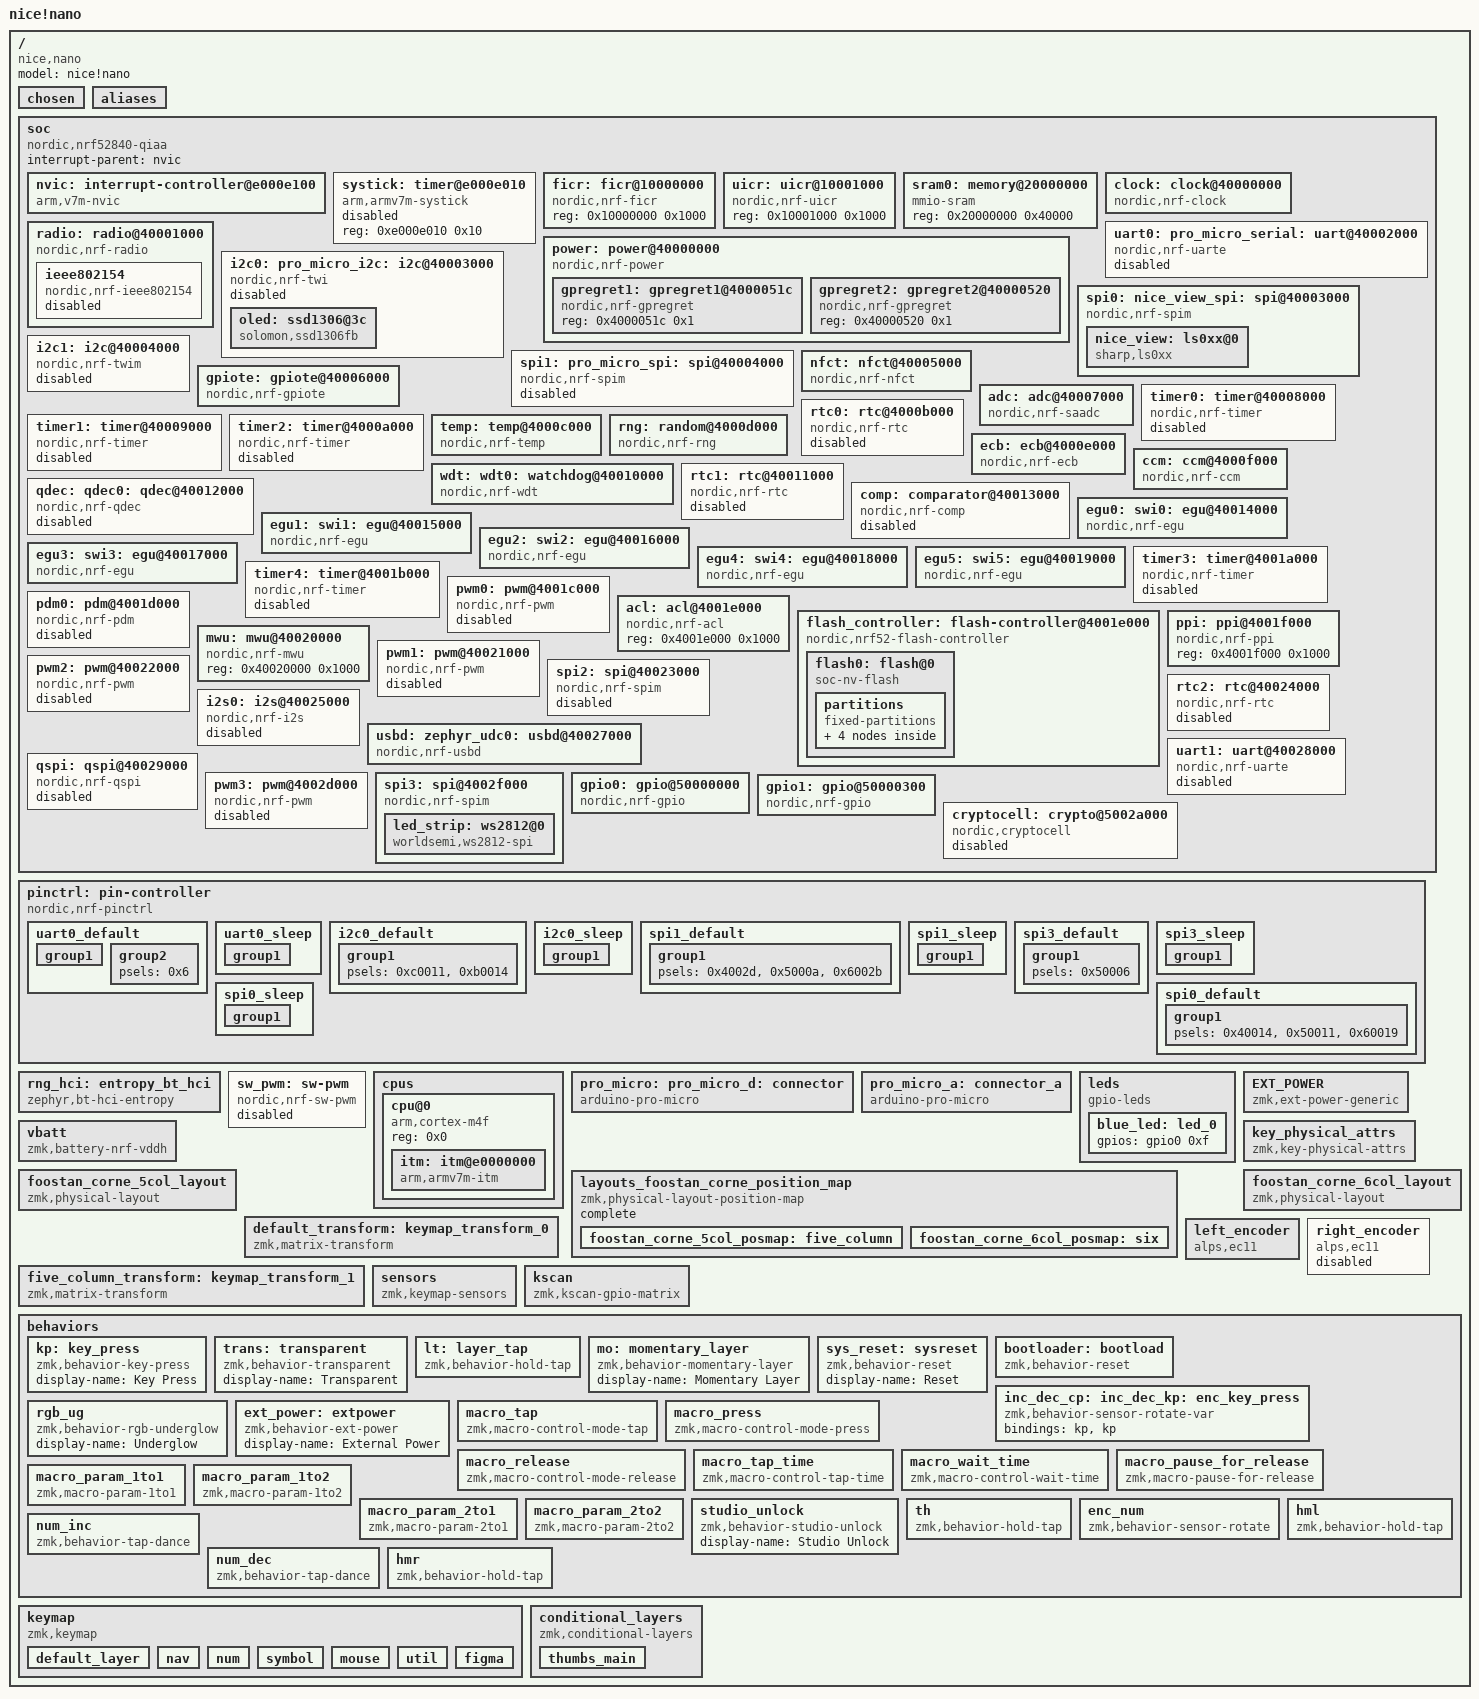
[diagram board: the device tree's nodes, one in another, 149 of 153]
/dts-v1/;

/ {
	#address-cells = < 0x1 >;
	#size-cells = < 0x1 >;
	model = "nice!nano";
	compatible = "nice,nano";
	chosen {
		zephyr,entropy = &rng;
		zephyr,flash-controller = &flash_controller;
		zephyr,code-partition = &code_partition;
		zephyr,sram = &sram0;
		zephyr,flash = &flash0;
		zmk,battery = &vbatt;
		zephyr,display = &nice_view;
		zmk,physical-layout = &foostan_corne_6col_layout;
		zmk,kscan = &kscan;
		zmk,underglow = &led_strip;
	};
	aliases {
	};
	soc {
		#address-cells = < 0x1 >;
		#size-cells = < 0x1 >;
		compatible = "nordic,nrf52840-qiaa", "nordic,nrf52840", "nordic,nrf52", "simple-bus";
		interrupt-parent = < &nvic >;
		ranges;
		nvic: interrupt-controller@e000e100 {
			#address-cells = < 0x1 >;
			compatible = "arm,v7m-nvic";
			reg = < 0xe000e100 0xc00 >;
			interrupt-controller;
			#interrupt-cells = < 0x2 >;
			arm,num-irq-priority-bits = < 0x3 >;
			phandle = < 0x1 >;
		};
		systick: timer@e000e010 {
			compatible = "arm,armv7m-systick";
			reg = < 0xe000e010 0x10 >;
			status = "disabled";
		};
		ficr: ficr@10000000 {
			compatible = "nordic,nrf-ficr";
			reg = < 0x10000000 0x1000 >;
			status = "okay";
		};
		uicr: uicr@10001000 {
			compatible = "nordic,nrf-uicr";
			reg = < 0x10001000 0x1000 >;
			status = "okay";
		};
		sram0: memory@20000000 {
			compatible = "mmio-sram";
			reg = < 0x20000000 0x40000 >;
		};
		clock: clock@40000000 {
			compatible = "nordic,nrf-clock";
			reg = < 0x40000000 0x1000 >;
			interrupts = < 0x0 0x1 >;
			status = "okay";
		};
		power: power@40000000 {
			compatible = "nordic,nrf-power";
			reg = < 0x40000000 0x1000 >;
			interrupts = < 0x0 0x1 >;
			status = "okay";
			#address-cells = < 0x1 >;
			#size-cells = < 0x1 >;
			gpregret1: gpregret1@4000051c {
				#address-cells = < 0x1 >;
				#size-cells = < 0x1 >;
				compatible = "nordic,nrf-gpregret";
				reg = < 0x4000051c 0x1 >;
				status = "okay";
			};
			gpregret2: gpregret2@40000520 {
				#address-cells = < 0x1 >;
				#size-cells = < 0x1 >;
				compatible = "nordic,nrf-gpregret";
				reg = < 0x40000520 0x1 >;
				status = "okay";
			};
		};
		radio: radio@40001000 {
			compatible = "nordic,nrf-radio";
			reg = < 0x40001000 0x1000 >;
			interrupts = < 0x1 0x1 >;
			status = "okay";
			ieee802154-supported;
			ble-2mbps-supported;
			ble-coded-phy-supported;
			tx-high-power-supported;
			ieee802154: ieee802154 {
				compatible = "nordic,nrf-ieee802154";
				status = "disabled";
			};
		};
		uart0: pro_micro_serial: uart@40002000 {
			compatible = "nordic,nrf-uarte";
			reg = < 0x40002000 0x1000 >;
			interrupts = < 0x2 0x1 >;
			status = "disabled";
			current-speed = < 0x1c200 >;
			pinctrl-0 = < &uart0_default >;
			pinctrl-1 = < &uart0_sleep >;
			pinctrl-names = "default", "sleep";
		};
		i2c0: pro_micro_i2c: i2c@40003000 {
			compatible = "nordic,nrf-twi";
			#address-cells = < 0x1 >;
			#size-cells = < 0x0 >;
			reg = < 0x40003000 0x1000 >;
			clock-frequency = < 0x186a0 >;
			interrupts = < 0x3 0x1 >;
			easydma-maxcnt-bits = < 0x10 >;
			status = "disabled";
			pinctrl-0 = < &i2c0_default >;
			pinctrl-1 = < &i2c0_sleep >;
			pinctrl-names = "default", "sleep";
			oled: ssd1306@3c {
				compatible = "solomon,ssd1306fb";
				reg = < 0x3c >;
				width = < 0x80 >;
				height = < 0x20 >;
				segment-offset = < 0x0 >;
				page-offset = < 0x0 >;
				display-offset = < 0x0 >;
				multiplex-ratio = < 0x1f >;
				segment-remap;
				com-invdir;
				com-sequential;
				inversion-on;
				prechargep = < 0x22 >;
			};
		};
		spi0: nice_view_spi: spi@40003000 {
			compatible = "nordic,nrf-spim";
			#address-cells = < 0x1 >;
			#size-cells = < 0x0 >;
			reg = < 0x40003000 0x1000 >;
			interrupts = < 0x3 0x1 >;
			max-frequency = < 0x7a1200 >;
			easydma-maxcnt-bits = < 0x10 >;
			status = "okay";
			pinctrl-0 = < &spi0_default >;
			pinctrl-1 = < &spi0_sleep >;
			pinctrl-names = "default", "sleep";
			cs-gpios = < &pro_micro 0x1 0x0 >;
			nice_view: ls0xx@0 {
				compatible = "sharp,ls0xx";
				spi-max-frequency = < 0xf4240 >;
				reg = < 0x0 >;
				width = < 0xa0 >;
				height = < 0x44 >;
			};
		};
		i2c1: i2c@40004000 {
			compatible = "nordic,nrf-twim";
			#address-cells = < 0x1 >;
			#size-cells = < 0x0 >;
			reg = < 0x40004000 0x1000 >;
			clock-frequency = < 0x186a0 >;
			interrupts = < 0x4 0x1 >;
			easydma-maxcnt-bits = < 0x10 >;
			status = "disabled";
		};
		spi1: pro_micro_spi: spi@40004000 {
			compatible = "nordic,nrf-spim";
			#address-cells = < 0x1 >;
			#size-cells = < 0x0 >;
			reg = < 0x40004000 0x1000 >;
			interrupts = < 0x4 0x1 >;
			max-frequency = < 0x7a1200 >;
			easydma-maxcnt-bits = < 0x10 >;
			status = "disabled";
			pinctrl-0 = < &spi1_default >;
			pinctrl-1 = < &spi1_sleep >;
			pinctrl-names = "default", "sleep";
		};
		nfct: nfct@40005000 {
			compatible = "nordic,nrf-nfct";
			reg = < 0x40005000 0x1000 >;
			interrupts = < 0x5 0x1 >;
			status = "okay";
		};
		gpiote: gpiote@40006000 {
			compatible = "nordic,nrf-gpiote";
			reg = < 0x40006000 0x1000 >;
			interrupts = < 0x6 0x5 >;
			status = "okay";
		};
		adc: adc@40007000 {
			compatible = "nordic,nrf-saadc";
			reg = < 0x40007000 0x1000 >;
			interrupts = < 0x7 0x1 >;
			status = "okay";
			#io-channel-cells = < 0x1 >;
		};
		timer0: timer@40008000 {
			compatible = "nordic,nrf-timer";
			status = "disabled";
			reg = < 0x40008000 0x1000 >;
			cc-num = < 0x4 >;
			max-bit-width = < 0x20 >;
			interrupts = < 0x8 0x1 >;
			prescaler = < 0x0 >;
		};
		timer1: timer@40009000 {
			compatible = "nordic,nrf-timer";
			status = "disabled";
			reg = < 0x40009000 0x1000 >;
			cc-num = < 0x4 >;
			max-bit-width = < 0x20 >;
			interrupts = < 0x9 0x1 >;
			prescaler = < 0x0 >;
			phandle = < 0xd >;
		};
		timer2: timer@4000a000 {
			compatible = "nordic,nrf-timer";
			status = "disabled";
			reg = < 0x4000a000 0x1000 >;
			cc-num = < 0x4 >;
			max-bit-width = < 0x20 >;
			interrupts = < 0xa 0x1 >;
			prescaler = < 0x0 >;
		};
		rtc0: rtc@4000b000 {
			compatible = "nordic,nrf-rtc";
			reg = < 0x4000b000 0x1000 >;
			cc-num = < 0x3 >;
			interrupts = < 0xb 0x1 >;
			status = "disabled";
			clock-frequency = < 0x8000 >;
			prescaler = < 0x1 >;
		};
		temp: temp@4000c000 {
			compatible = "nordic,nrf-temp";
			reg = < 0x4000c000 0x1000 >;
			interrupts = < 0xc 0x1 >;
			status = "okay";
		};
		rng: random@4000d000 {
			compatible = "nordic,nrf-rng";
			reg = < 0x4000d000 0x1000 >;
			interrupts = < 0xd 0x1 >;
			status = "okay";
		};
		ecb: ecb@4000e000 {
			compatible = "nordic,nrf-ecb";
			reg = < 0x4000e000 0x1000 >;
			interrupts = < 0xe 0x1 >;
			status = "okay";
		};
		ccm: ccm@4000f000 {
			compatible = "nordic,nrf-ccm";
			reg = < 0x4000f000 0x1000 >;
			interrupts = < 0xf 0x1 >;
			length-field-length-8-bits;
			status = "okay";
		};
		wdt: wdt0: watchdog@40010000 {
			compatible = "nordic,nrf-wdt";
			reg = < 0x40010000 0x1000 >;
			interrupts = < 0x10 0x1 >;
			status = "okay";
		};
		rtc1: rtc@40011000 {
			compatible = "nordic,nrf-rtc";
			reg = < 0x40011000 0x1000 >;
			cc-num = < 0x4 >;
			interrupts = < 0x11 0x1 >;
			status = "disabled";
			clock-frequency = < 0x8000 >;
			prescaler = < 0x1 >;
		};
		qdec: qdec0: qdec@40012000 {
			compatible = "nordic,nrf-qdec";
			reg = < 0x40012000 0x1000 >;
			interrupts = < 0x12 0x1 >;
			status = "disabled";
		};
		comp: comparator@40013000 {
			compatible = "nordic,nrf-comp";
			reg = < 0x40013000 0x1000 >;
			interrupts = < 0x13 0x1 >;
			status = "disabled";
			#io-channel-cells = < 0x1 >;
		};
		egu0: swi0: egu@40014000 {
			compatible = "nordic,nrf-egu", "nordic,nrf-swi";
			reg = < 0x40014000 0x1000 >;
			interrupts = < 0x14 0x1 >;
			status = "okay";
		};
		egu1: swi1: egu@40015000 {
			compatible = "nordic,nrf-egu", "nordic,nrf-swi";
			reg = < 0x40015000 0x1000 >;
			interrupts = < 0x15 0x1 >;
			status = "okay";
		};
		egu2: swi2: egu@40016000 {
			compatible = "nordic,nrf-egu", "nordic,nrf-swi";
			reg = < 0x40016000 0x1000 >;
			interrupts = < 0x16 0x1 >;
			status = "okay";
		};
		egu3: swi3: egu@40017000 {
			compatible = "nordic,nrf-egu", "nordic,nrf-swi";
			reg = < 0x40017000 0x1000 >;
			interrupts = < 0x17 0x1 >;
			status = "okay";
		};
		egu4: swi4: egu@40018000 {
			compatible = "nordic,nrf-egu", "nordic,nrf-swi";
			reg = < 0x40018000 0x1000 >;
			interrupts = < 0x18 0x1 >;
			status = "okay";
		};
		egu5: swi5: egu@40019000 {
			compatible = "nordic,nrf-egu", "nordic,nrf-swi";
			reg = < 0x40019000 0x1000 >;
			interrupts = < 0x19 0x1 >;
			status = "okay";
		};
		timer3: timer@4001a000 {
			compatible = "nordic,nrf-timer";
			status = "disabled";
			reg = < 0x4001a000 0x1000 >;
			cc-num = < 0x6 >;
			max-bit-width = < 0x20 >;
			interrupts = < 0x1a 0x1 >;
			prescaler = < 0x0 >;
		};
		timer4: timer@4001b000 {
			compatible = "nordic,nrf-timer";
			status = "disabled";
			reg = < 0x4001b000 0x1000 >;
			cc-num = < 0x6 >;
			max-bit-width = < 0x20 >;
			interrupts = < 0x1b 0x1 >;
			prescaler = < 0x0 >;
		};
		pwm0: pwm@4001c000 {
			compatible = "nordic,nrf-pwm";
			reg = < 0x4001c000 0x1000 >;
			interrupts = < 0x1c 0x1 >;
			status = "disabled";
			#pwm-cells = < 0x3 >;
		};
		pdm0: pdm@4001d000 {
			compatible = "nordic,nrf-pdm";
			reg = < 0x4001d000 0x1000 >;
			interrupts = < 0x1d 0x1 >;
			status = "disabled";
		};
		acl: acl@4001e000 {
			compatible = "nordic,nrf-acl";
			reg = < 0x4001e000 0x1000 >;
			status = "okay";
		};
		flash_controller: flash-controller@4001e000 {
			compatible = "nordic,nrf52-flash-controller";
			reg = < 0x4001e000 0x1000 >;
			partial-erase;
			#address-cells = < 0x1 >;
			#size-cells = < 0x1 >;
			flash0: flash@0 {
				compatible = "soc-nv-flash";
				erase-block-size = < 0x1000 >;
				write-block-size = < 0x4 >;
				reg = < 0x0 0x100000 >;
				partitions {
					compatible = "fixed-partitions";
					#address-cells = < 0x1 >;
					#size-cells = < 0x1 >;
					sd_partition: partition@0 {
						reg = < 0x0 0x26000 >;
					};
					code_partition: partition@26000 {
						reg = < 0x26000 0xc6000 >;
					};
					storage_partition: partition@ec000 {
						reg = < 0xec000 0x8000 >;
					};
					boot_partition: partition@f4000 {
						reg = < 0xf4000 0xc000 >;
					};
				};
			};
		};
		ppi: ppi@4001f000 {
			compatible = "nordic,nrf-ppi";
			reg = < 0x4001f000 0x1000 >;
			status = "okay";
		};
		mwu: mwu@40020000 {
			compatible = "nordic,nrf-mwu";
			reg = < 0x40020000 0x1000 >;
			status = "okay";
		};
		pwm1: pwm@40021000 {
			compatible = "nordic,nrf-pwm";
			reg = < 0x40021000 0x1000 >;
			interrupts = < 0x21 0x1 >;
			status = "disabled";
			#pwm-cells = < 0x3 >;
		};
		pwm2: pwm@40022000 {
			compatible = "nordic,nrf-pwm";
			reg = < 0x40022000 0x1000 >;
			interrupts = < 0x22 0x1 >;
			status = "disabled";
			#pwm-cells = < 0x3 >;
		};
		spi2: spi@40023000 {
			compatible = "nordic,nrf-spim";
			#address-cells = < 0x1 >;
			#size-cells = < 0x0 >;
			reg = < 0x40023000 0x1000 >;
			interrupts = < 0x23 0x1 >;
			max-frequency = < 0x7a1200 >;
			easydma-maxcnt-bits = < 0x10 >;
			status = "disabled";
		};
		rtc2: rtc@40024000 {
			compatible = "nordic,nrf-rtc";
			reg = < 0x40024000 0x1000 >;
			cc-num = < 0x4 >;
			interrupts = < 0x24 0x1 >;
			status = "disabled";
			clock-frequency = < 0x8000 >;
			prescaler = < 0x1 >;
		};
		i2s0: i2s@40025000 {
			compatible = "nordic,nrf-i2s";
			#address-cells = < 0x1 >;
			#size-cells = < 0x0 >;
			reg = < 0x40025000 0x1000 >;
			interrupts = < 0x25 0x1 >;
			status = "disabled";
		};
		usbd: zephyr_udc0: usbd@40027000 {
			compatible = "nordic,nrf-usbd";
			reg = < 0x40027000 0x1000 >;
			interrupts = < 0x27 0x1 >;
			num-bidir-endpoints = < 0x1 >;
			num-in-endpoints = < 0x7 >;
			num-out-endpoints = < 0x7 >;
			num-isoin-endpoints = < 0x1 >;
			num-isoout-endpoints = < 0x1 >;
			status = "okay";
		};
		uart1: uart@40028000 {
			compatible = "nordic,nrf-uarte";
			reg = < 0x40028000 0x1000 >;
			interrupts = < 0x28 0x1 >;
			status = "disabled";
		};
		qspi: qspi@40029000 {
			compatible = "nordic,nrf-qspi";
			#address-cells = < 0x1 >;
			#size-cells = < 0x0 >;
			reg = < 0x40029000 0x1000 >, < 0x12000000 0x8000000 >;
			reg-names = "qspi", "qspi_mm";
			interrupts = < 0x29 0x1 >;
			status = "disabled";
		};
		pwm3: pwm@4002d000 {
			compatible = "nordic,nrf-pwm";
			reg = < 0x4002d000 0x1000 >;
			interrupts = < 0x2d 0x1 >;
			status = "disabled";
			#pwm-cells = < 0x3 >;
		};
		spi3: spi@4002f000 {
			compatible = "nordic,nrf-spim";
			#address-cells = < 0x1 >;
			#size-cells = < 0x0 >;
			reg = < 0x4002f000 0x1000 >;
			interrupts = < 0x2f 0x1 >;
			max-frequency = < 0x1e84800 >;
			easydma-maxcnt-bits = < 0x10 >;
			rx-delay-supported;
			rx-delay = < 0x2 >;
			status = "okay";
			pinctrl-0 = < &spi3_default >;
			pinctrl-1 = < &spi3_sleep >;
			pinctrl-names = "default", "sleep";
			led_strip: ws2812@0 {
				compatible = "worldsemi,ws2812-spi";
				reg = < 0x0 >;
				spi-max-frequency = < 0x3d0900 >;
				chain-length = < 0xa >;
				spi-one-frame = < 0x70 >;
				spi-zero-frame = < 0x40 >;
				color-mapping = < 0x2 0x1 0x3 >;
			};
		};
		gpio0: gpio@50000000 {
			compatible = "nordic,nrf-gpio";
			gpio-controller;
			reg = < 0x50000000 0x200 0x50000500 0x300 >;
			#gpio-cells = < 0x2 >;
			status = "okay";
			port = < 0x0 >;
			phandle = < 0xe >;
		};
		gpio1: gpio@50000300 {
			compatible = "nordic,nrf-gpio";
			gpio-controller;
			reg = < 0x50000300 0x200 0x50000800 0x300 >;
			#gpio-cells = < 0x2 >;
			ngpios = < 0x10 >;
			status = "okay";
			port = < 0x1 >;
			phandle = < 0xf >;
		};
		cryptocell: crypto@5002a000 {
			compatible = "nordic,cryptocell", "arm,cryptocell-310";
			reg = < 0x5002a000 0x1000 >, < 0x5002b000 0x1000 >;
			reg-names = "wrapper", "core";
			interrupts = < 0x2a 0x1 >;
			status = "disabled";
		};
	};
	pinctrl: pin-controller {
		compatible = "nordic,nrf-pinctrl";
		uart0_default: uart0_default {
			phandle = < 0x2 >;
			group1 {
				psels = < 0x10008 >;
				bias-pull-up;
			};
			group2 {
				psels = < 0x6 >;
			};
		};
		uart0_sleep: uart0_sleep {
			phandle = < 0x3 >;
			group1 {
				psels = < 0x10008 >, < 0x6 >;
				low-power-enable;
			};
		};
		i2c0_default: i2c0_default {
			phandle = < 0x4 >;
			group1 {
				psels = < 0xc0011 >, < 0xb0014 >;
			};
		};
		i2c0_sleep: i2c0_sleep {
			phandle = < 0x5 >;
			group1 {
				psels = < 0xc0011 >, < 0xb0014 >;
				low-power-enable;
			};
		};
		spi1_default: spi1_default {
			phandle = < 0x9 >;
			group1 {
				psels = < 0x4002d >, < 0x5000a >, < 0x6002b >;
			};
		};
		spi1_sleep: spi1_sleep {
			phandle = < 0xa >;
			group1 {
				psels = < 0x4002d >, < 0x5000a >, < 0x6002b >;
				low-power-enable;
			};
		};
		spi3_default: spi3_default {
			phandle = < 0xb >;
			group1 {
				psels = < 0x50006 >;
			};
		};
		spi3_sleep: spi3_sleep {
			phandle = < 0xc >;
			group1 {
				psels = < 0x50006 >;
				low-power-enable;
			};
		};
		spi0_default: spi0_default {
			phandle = < 0x6 >;
			group1 {
				psels = < 0x40014 >, < 0x50011 >, < 0x60019 >;
			};
		};
		spi0_sleep: spi0_sleep {
			phandle = < 0x7 >;
			group1 {
				psels = < 0x40014 >, < 0x50011 >, < 0x60019 >;
				low-power-enable;
			};
		};
	};
	rng_hci: entropy_bt_hci {
		compatible = "zephyr,bt-hci-entropy";
		status = "okay";
	};
	sw_pwm: sw-pwm {
		compatible = "nordic,nrf-sw-pwm";
		status = "disabled";
		generator = < &timer1 >;
		clock-prescaler = < 0x0 >;
		#pwm-cells = < 0x3 >;
	};
	cpus {
		#address-cells = < 0x1 >;
		#size-cells = < 0x0 >;
		cpu@0 {
			device_type = "cpu";
			compatible = "arm,cortex-m4f";
			reg = < 0x0 >;
			#address-cells = < 0x1 >;
			#size-cells = < 0x1 >;
			itm: itm@e0000000 {
				compatible = "arm,armv7m-itm";
				reg = < 0xe0000000 0x1000 >;
				swo-ref-frequency = < 0x1e84800 >;
			};
		};
	};
	pro_micro: pro_micro_d: connector {
		compatible = "arduino-pro-micro";
		#gpio-cells = < 0x2 >;
		gpio-map-mask = < 0xffffffff 0xffffffc0 >;
		gpio-map-pass-thru = < 0x0 0x3f >;
		gpio-map = < 0x0 0x0 &gpio0 0x8 0x0 >, < 0x1 0x0 &gpio0 0x6 0x0 >, < 0x2 0x0 &gpio0 0x11 0x0 >, < 0x3 0x0 &gpio0 0x14 0x0 >, < 0x4 0x0 &gpio0 0x16 0x0 >, < 0x5 0x0 &gpio0 0x18 0x0 >, < 0x6 0x0 &gpio1 0x0 0x0 >, < 0x7 0x0 &gpio0 0xb 0x0 >, < 0x8 0x0 &gpio1 0x4 0x0 >, < 0x9 0x0 &gpio1 0x6 0x0 >, < 0xa 0x0 &gpio0 0x9 0x0 >, < 0x10 0x0 &gpio0 0xa 0x0 >, < 0xe 0x0 &gpio1 0xb 0x0 >, < 0xf 0x0 &gpio1 0xd 0x0 >, < 0x12 0x0 &gpio1 0xf 0x0 >, < 0x13 0x0 &gpio0 0x2 0x0 >, < 0x14 0x0 &gpio0 0x1d 0x0 >, < 0x15 0x0 &gpio0 0x1f 0x0 >;
		phandle = < 0x8 >;
	};
	pro_micro_a: connector_a {
		compatible = "arduino-pro-micro";
		#gpio-cells = < 0x2 >;
		gpio-map-mask = < 0xffffffff 0xffffffc0 >;
		gpio-map-pass-thru = < 0x0 0x3f >;
		gpio-map = < 0x0 0x0 &gpio1 0xf 0x0 >, < 0x1 0x0 &gpio0 0x2 0x0 >, < 0x2 0x0 &gpio0 0x1d 0x0 >, < 0x3 0x0 &gpio0 0x1f 0x0 >, < 0x6 0x0 &gpio0 0x16 0x0 >, < 0x7 0x0 &gpio1 0x0 0x0 >, < 0x8 0x0 &gpio1 0x4 0x0 >, < 0x9 0x0 &gpio1 0x6 0x0 >, < 0xa 0x0 &gpio0 0x9 0x0 >;
	};
	leds {
		compatible = "gpio-leds";
		blue_led: led_0 {
			gpios = < &gpio0 0xf 0x0 >;
		};
	};
	EXT_POWER {
		compatible = "zmk,ext-power-generic";
		control-gpios = < &gpio0 0xd 0x0 >;
		init-delay-ms = < 0x32 >;
	};
	vbatt: vbatt {
		compatible = "zmk,battery-nrf-vddh";
	};
	layouts_foostan_corne_position_map: layouts_foostan_corne_position_map {
		compatible = "zmk,physical-layout-position-map";
		complete;
		foostan_corne_5col_posmap: five_column {
			physical-layout = < &foostan_corne_5col_layout >;
			positions = < 0x24 0x0 0x1 0x2 0x3 0x4 0x5 0x6 0x7 0x8 0x9 0x25 >, < 0x26 0xa 0xb 0xc 0xd 0xe 0xf 0x10 0x11 0x12 0x13 0x27 >, < 0x28 0x14 0x15 0x16 0x17 0x18 0x19 0x1a 0x1b 0x1c 0x1d 0x29 >, < 0x1e 0x1f 0x20 0x21 0x22 0x23 >;
		};
		foostan_corne_6col_posmap: six {
			physical-layout = < &foostan_corne_6col_layout >;
			positions = < 0x0 0x1 0x2 0x3 0x4 0x5 0x6 0x7 0x8 0x9 0xa 0xb >, < 0xc 0xd 0xe 0xf 0x10 0x11 0x12 0x13 0x14 0x15 0x16 0x17 >, < 0x18 0x19 0x1a 0x1b 0x1c 0x1d 0x1e 0x1f 0x20 0x21 0x22 0x23 >, < 0x24 0x25 0x26 0x27 0x28 0x29 >;
		};
	};
	key_physical_attrs: key_physical_attrs {
		compatible = "zmk,key-physical-attrs";
		#key-cells = < 0x7 >;
		phandle = < 0x12 >;
	};
	foostan_corne_5col_layout: foostan_corne_5col_layout {
		compatible = "zmk,physical-layout";
		display-name = "5 Column";
		keys = < &key_physical_attrs 0x64 0x64 0x0 0x25 0x0 0x0 0x0 >, < &key_physical_attrs 0x64 0x64 0x64 0xc 0x0 0x0 0x0 >, < &key_physical_attrs 0x64 0x64 0xc8 0x0 0x0 0x0 0x0 >, < &key_physical_attrs 0x64 0x64 0x12c 0xc 0x0 0x0 0x0 >, < &key_physical_attrs 0x64 0x64 0x190 0x18 0x0 0x0 0x0 >, < &key_physical_attrs 0x64 0x64 0x2bc 0x18 0x0 0x0 0x0 >, < &key_physical_attrs 0x64 0x64 0x320 0xc 0x0 0x0 0x0 >, < &key_physical_attrs 0x64 0x64 0x384 0x0 0x0 0x0 0x0 >, < &key_physical_attrs 0x64 0x64 0x3e8 0xc 0x0 0x0 0x0 >, < &key_physical_attrs 0x64 0x64 0x44c 0x25 0x0 0x0 0x0 >, < &key_physical_attrs 0x64 0x64 0x0 0x89 0x0 0x0 0x0 >, < &key_physical_attrs 0x64 0x64 0x64 0x70 0x0 0x0 0x0 >, < &key_physical_attrs 0x64 0x64 0xc8 0x64 0x0 0x0 0x0 >, < &key_physical_attrs 0x64 0x64 0x12c 0x70 0x0 0x0 0x0 >, < &key_physical_attrs 0x64 0x64 0x190 0x7c 0x0 0x0 0x0 >, < &key_physical_attrs 0x64 0x64 0x2bc 0x7c 0x0 0x0 0x0 >, < &key_physical_attrs 0x64 0x64 0x320 0x70 0x0 0x0 0x0 >, < &key_physical_attrs 0x64 0x64 0x384 0x64 0x0 0x0 0x0 >, < &key_physical_attrs 0x64 0x64 0x3e8 0x70 0x0 0x0 0x0 >, < &key_physical_attrs 0x64 0x64 0x44c 0x89 0x0 0x0 0x0 >, < &key_physical_attrs 0x64 0x64 0x0 0xed 0x0 0x0 0x0 >, < &key_physical_attrs 0x64 0x64 0x64 0xd4 0x0 0x0 0x0 >, < &key_physical_attrs 0x64 0x64 0xc8 0xc8 0x0 0x0 0x0 >, < &key_physical_attrs 0x64 0x64 0x12c 0xd4 0x0 0x0 0x0 >, < &key_physical_attrs 0x64 0x64 0x190 0xe0 0x0 0x0 0x0 >, < &key_physical_attrs 0x64 0x64 0x2bc 0xe0 0x0 0x0 0x0 >, < &key_physical_attrs 0x64 0x64 0x320 0xd4 0x0 0x0 0x0 >, < &key_physical_attrs 0x64 0x64 0x384 0xc8 0x0 0x0 0x0 >, < &key_physical_attrs 0x64 0x64 0x3e8 0xd4 0x0 0x0 0x0 >, < &key_physical_attrs 0x64 0x64 0x44c 0xed 0x0 0x0 0x0 >, < &key_physical_attrs 0x64 0x64 0xfa 0x138 0x0 0x0 0x0 >, < &key_physical_attrs 0x64 0x64 0x15e 0x138 0x4b0 0x15e 0x19c >, < &key_physical_attrs 0x64 0x96 0x1c0 0x11b 0x960 0x1c0 0x1b1 >, < &key_physical_attrs 0x64 0x96 0x28c 0x11b 0xfffff6a0 0x2f0 0x1b1 >, < &key_physical_attrs 0x64 0x64 0x2ee 0x138 0xfffffb50 0x352 0x19c >, < &key_physical_attrs 0x64 0x64 0x352 0x138 0x0 0x0 0x0 >;
		transform = < &five_column_transform >;
		phandle = < 0x10 >;
	};
	foostan_corne_6col_layout: foostan_corne_6col_layout {
		compatible = "zmk,physical-layout";
		display-name = "6 Column";
		keys = < &key_physical_attrs 0x64 0x64 0x0 0x25 0x0 0x0 0x0 >, < &key_physical_attrs 0x64 0x64 0x64 0x25 0x0 0x0 0x0 >, < &key_physical_attrs 0x64 0x64 0xc8 0xc 0x0 0x0 0x0 >, < &key_physical_attrs 0x64 0x64 0x12c 0x0 0x0 0x0 0x0 >, < &key_physical_attrs 0x64 0x64 0x190 0xc 0x0 0x0 0x0 >, < &key_physical_attrs 0x64 0x64 0x1f4 0x18 0x0 0x0 0x0 >, < &key_physical_attrs 0x64 0x64 0x320 0x18 0x0 0x0 0x0 >, < &key_physical_attrs 0x64 0x64 0x384 0xc 0x0 0x0 0x0 >, < &key_physical_attrs 0x64 0x64 0x3e8 0x0 0x0 0x0 0x0 >, < &key_physical_attrs 0x64 0x64 0x44c 0xc 0x0 0x0 0x0 >, < &key_physical_attrs 0x64 0x64 0x4b0 0x25 0x0 0x0 0x0 >, < &key_physical_attrs 0x64 0x64 0x514 0x25 0x0 0x0 0x0 >, < &key_physical_attrs 0x64 0x64 0x0 0x89 0x0 0x0 0x0 >, < &key_physical_attrs 0x64 0x64 0x64 0x89 0x0 0x0 0x0 >, < &key_physical_attrs 0x64 0x64 0xc8 0x70 0x0 0x0 0x0 >, < &key_physical_attrs 0x64 0x64 0x12c 0x64 0x0 0x0 0x0 >, < &key_physical_attrs 0x64 0x64 0x190 0x70 0x0 0x0 0x0 >, < &key_physical_attrs 0x64 0x64 0x1f4 0x7c 0x0 0x0 0x0 >, < &key_physical_attrs 0x64 0x64 0x320 0x7c 0x0 0x0 0x0 >, < &key_physical_attrs 0x64 0x64 0x384 0x70 0x0 0x0 0x0 >, < &key_physical_attrs 0x64 0x64 0x3e8 0x64 0x0 0x0 0x0 >, < &key_physical_attrs 0x64 0x64 0x44c 0x70 0x0 0x0 0x0 >, < &key_physical_attrs 0x64 0x64 0x4b0 0x89 0x0 0x0 0x0 >, < &key_physical_attrs 0x64 0x64 0x514 0x89 0x0 0x0 0x0 >, < &key_physical_attrs 0x64 0x64 0x0 0xed 0x0 0x0 0x0 >, < &key_physical_attrs 0x64 0x64 0x64 0xed 0x0 0x0 0x0 >, < &key_physical_attrs 0x64 0x64 0xc8 0xd4 0x0 0x0 0x0 >, < &key_physical_attrs 0x64 0x64 0x12c 0xc8 0x0 0x0 0x0 >, < &key_physical_attrs 0x64 0x64 0x190 0xd4 0x0 0x0 0x0 >, < &key_physical_attrs 0x64 0x64 0x1f4 0xe0 0x0 0x0 0x0 >, < &key_physical_attrs 0x64 0x64 0x320 0xe0 0x0 0x0 0x0 >, < &key_physical_attrs 0x64 0x64 0x384 0xd4 0x0 0x0 0x0 >, < &key_physical_attrs 0x64 0x64 0x3e8 0xc8 0x0 0x0 0x0 >, < &key_physical_attrs 0x64 0x64 0x44c 0xd4 0x0 0x0 0x0 >, < &key_physical_attrs 0x64 0x64 0x4b0 0xed 0x0 0x0 0x0 >, < &key_physical_attrs 0x64 0x64 0x514 0xed 0x0 0x0 0x0 >, < &key_physical_attrs 0x64 0x64 0x15e 0x138 0x0 0x0 0x0 >, < &key_physical_attrs 0x64 0x64 0x1c2 0x138 0x4b0 0x1c2 0x19c >, < &key_physical_attrs 0x64 0x96 0x224 0x11b 0x960 0x224 0x1b1 >, < &key_physical_attrs 0x64 0x96 0x2f0 0x11b 0xfffff6a0 0x354 0x1b1 >, < &key_physical_attrs 0x64 0x64 0x352 0x138 0xfffffb50 0x3b6 0x19c >, < &key_physical_attrs 0x64 0x64 0x3b6 0x138 0x0 0x0 0x0 >;
		transform = < &default_transform >;
		phandle = < 0x11 >;
	};
	default_transform: keymap_transform_0 {
		compatible = "zmk,matrix-transform";
		columns = < 0xc >;
		rows = < 0x4 >;
		map = < 0x0 0x1 0x2 0x3 0x4 0x5 0x6 0x7 0x8 0x9 0xa 0xb 0x100 0x101 0x102 0x103 0x104 0x105 0x106 0x107 0x108 0x109 0x10a 0x10b 0x200 0x201 0x202 0x203 0x204 0x205 0x206 0x207 0x208 0x209 0x20a 0x20b 0x303 0x304 0x305 0x306 0x307 0x308 >;
		phandle = < 0x14 >;
	};
	five_column_transform: keymap_transform_1 {
		compatible = "zmk,matrix-transform";
		columns = < 0xa >;
		rows = < 0x4 >;
		map = < 0x1 0x2 0x3 0x4 0x5 0x6 0x7 0x8 0x9 0xa 0x101 0x102 0x103 0x104 0x105 0x106 0x107 0x108 0x109 0x10a 0x201 0x202 0x203 0x204 0x205 0x206 0x207 0x208 0x209 0x20a 0x303 0x304 0x305 0x306 0x307 0x308 >;
		phandle = < 0x13 >;
	};
	left_encoder: left_encoder {
		compatible = "alps,ec11";
		steps = < 0x1e >;
		status = "okay";
		a-gpios = < &pro_micro 0x4 0x10 >;
		b-gpios = < &pro_micro 0x5 0x10 >;
		phandle = < 0x15 >;
	};
	right_encoder: right_encoder {
		compatible = "alps,ec11";
		steps = < 0x1e >;
		status = "disabled";
		a-gpios = < &pro_micro 0x13 0x10 >;
		b-gpios = < &pro_micro 0x12 0x10 >;
		phandle = < 0x16 >;
	};
	sensors: sensors {
		compatible = "zmk,keymap-sensors";
		sensors = < &left_encoder &right_encoder >;
		triggers-per-rotation = < 0x14 >;
	};
	kscan: kscan {
		compatible = "zmk,kscan-gpio-matrix";
		wakeup-source;
		diode-direction = "col2row";
		row-gpios = < &pro_micro 0x6 0x20 >, < &pro_micro 0x7 0x20 >, < &pro_micro 0x8 0x20 >, < &pro_micro 0x9 0x20 >;
		col-gpios = < &pro_micro 0x10 0x0 >, < &pro_micro 0xa 0x0 >, < &pro_micro 0xe 0x0 >, < &pro_micro 0xf 0x0 >, < &pro_micro 0x12 0x0 >, < &pro_micro 0x13 0x0 >;
	};
	behaviors {
		kp: key_press {
			compatible = "zmk,behavior-key-press";
			#binding-cells = < 0x1 >;
			display-name = "Key Press";
			phandle = < 0x17 >;
		};
		trans: transparent {
			compatible = "zmk,behavior-transparent";
			#binding-cells = < 0x0 >;
			display-name = "Transparent";
			phandle = < 0x20 >;
		};
		lt: layer_tap {
			compatible = "zmk,behavior-hold-tap";
			#binding-cells = < 0x2 >;
			flavor = "tap-preferred";
			tapping-term-ms = < 0xc8 >;
			bindings = < &mo >, < &kp >;
			display-name = "Layer-Tap";
			phandle = < 0x1e >;
		};
		mo: momentary_layer {
			compatible = "zmk,behavior-momentary-layer";
			#binding-cells = < 0x1 >;
			display-name = "Momentary Layer";
			phandle = < 0x18 >;
		};
		sys_reset: sysreset {
			compatible = "zmk,behavior-reset";
			#binding-cells = < 0x0 >;
			display-name = "Reset";
		};
		bootloader: bootload {
			compatible = "zmk,behavior-reset";
			type = < 0x57 >;
			#binding-cells = < 0x0 >;
			display-name = "Bootloader";
		};
		inc_dec_cp: inc_dec_kp: enc_key_press {
			compatible = "zmk,behavior-sensor-rotate-var";
			#sensor-binding-cells = < 0x2 >;
			bindings = < &kp >, < &kp >;
			phandle = < 0x1f >;
		};
		rgb_ug: rgb_ug {
			compatible = "zmk,behavior-rgb-underglow";
			#binding-cells = < 0x2 >;
			display-name = "Underglow";
		};
		ext_power: extpower {
			compatible = "zmk,behavior-ext-power";
			#binding-cells = < 0x1 >;
			display-name = "External Power";
		};
		macro_tap: macro_tap {
			compatible = "zmk,macro-control-mode-tap";
			#binding-cells = < 0x0 >;
		};
		macro_press: macro_press {
			compatible = "zmk,macro-control-mode-press";
			#binding-cells = < 0x0 >;
		};
		macro_release: macro_release {
			compatible = "zmk,macro-control-mode-release";
			#binding-cells = < 0x0 >;
		};
		macro_tap_time: macro_tap_time {
			compatible = "zmk,macro-control-tap-time";
			#binding-cells = < 0x1 >;
		};
		macro_wait_time: macro_wait_time {
			compatible = "zmk,macro-control-wait-time";
			#binding-cells = < 0x1 >;
		};
		macro_pause_for_release: macro_pause_for_release {
			compatible = "zmk,macro-pause-for-release";
			#binding-cells = < 0x0 >;
		};
		macro_param_1to1: macro_param_1to1 {
			compatible = "zmk,macro-param-1to1";
			#binding-cells = < 0x0 >;
		};
		macro_param_1to2: macro_param_1to2 {
			compatible = "zmk,macro-param-1to2";
			#binding-cells = < 0x0 >;
		};
		macro_param_2to1: macro_param_2to1 {
			compatible = "zmk,macro-param-2to1";
			#binding-cells = < 0x0 >;
		};
		macro_param_2to2: macro_param_2to2 {
			compatible = "zmk,macro-param-2to2";
			#binding-cells = < 0x0 >;
		};
		studio_unlock: studio_unlock {
			compatible = "zmk,behavior-studio-unlock";
			#binding-cells = < 0x0 >;
			display-name = "Studio Unlock";
		};
		th: th {
			compatible = "zmk,behavior-hold-tap";
			label = "TAPHOLD";
			bindings = < &kp >, < &kp >;
			#binding-cells = < 0x2 >;
			tapping-term-ms = < 0xc8 >;
			quick-tap-ms = < 0x7d >;
			phandle = < 0x1b >;
		};
		enc_num: enc_num {
			compatible = "zmk,behavior-sensor-rotate";
			label = "ENC_NUM";
			#sensor-binding-cells = < 0x0 >;
			bindings = < &num_inc >, < &num_dec >;
			phandle = < 0x21 >;
		};
		num_inc: num_inc {
			compatible = "zmk,behavior-tap-dance";
			label = "NUM_INC";
			#binding-cells = < 0x0 >;
			bindings = < &kp 0x70027 >, < &kp 0x7001e >, < &kp 0x7001f >, < &kp 0x70020 >, < &kp 0x70021 >, < &kp 0x70022 >, < &kp 0x70023 >, < &kp 0x70024 >, < &kp 0x70025 >, < &kp 0x70026 >;
			phandle = < 0x19 >;
		};
		num_dec: num_dec {
			compatible = "zmk,behavior-tap-dance";
			label = "NUM_DEC";
			#binding-cells = < 0x0 >;
			bindings = < &kp 0x70026 >, < &kp 0x70025 >, < &kp 0x70024 >, < &kp 0x70023 >, < &kp 0x70022 >, < &kp 0x70021 >, < &kp 0x70020 >, < &kp 0x7001f >, < &kp 0x7001e >, < &kp 0x70027 >;
			phandle = < 0x1a >;
		};
		hml: hml {
			compatible = "zmk,behavior-hold-tap";
			label = "HOMEROW_MODS_LEFT_HAND";
			bindings = < &kp >, < &kp >;
			#binding-cells = < 0x2 >;
			tapping-term-ms = < 0xc8 >;
			hold-trigger-key-positions = < 0x6 0x7 0x12 0x1e 0x27 0x28 0x29 0x1f 0xa 0x8 0x15 0x13 0x14 0x22 0x21 0x20 0x17 0x16 0x23 0xb 0x9 >;
			phandle = < 0x1c >;
		};
		hmr: hmr {
			compatible = "zmk,behavior-hold-tap";
			label = "HOMEROW_MODS_RIGHT_HAND";
			bindings = < &kp >, < &kp >;
			#binding-cells = < 0x2 >;
			tapping-term-ms = < 0xc8 >;
			hold-trigger-key-positions = < 0x1 0xc 0x0 0xd 0x2 0x3 0x4 0x5 0xe 0x10 0xf 0x11 0x1d 0x26 0x25 0x24 0x1c 0x1b 0x1a 0x19 0x18 >;
			phandle = < 0x1d >;
		};
	};
	keymap {
		compatible = "zmk,keymap";
		default_layer {
			bindings = < &th 0x50700e3 0x70028 &kp 0x70014 &kp 0x7001a &kp 0x70008 &kp 0x70015 &kp 0x70017 &kp 0x7001c &kp 0x70018 &kp 0x7000c &kp 0x70012 &kp 0x70013 &th 0x50700e3 0x70035 &th 0x70700e3 0x70029 &hml 0x700e1 0x70004 &hml 0x700e0 0x70016 &hml 0x700e2 0x70007 &hml 0x700e3 0x70009 &kp 0x7000a &kp 0x7000b &hmr 0x700e7 0x7000d &hmr 0x700e6 0x7000e &hmr 0x700e4 0x7000f &hmr 0x700e5 0x70033 &hmr 0x700700e7 0x70034 &th 0x60700e0 0x7002a &kp 0x7001d &kp 0x7001b &kp 0x70006 &kp 0x70019 &kp 0x70005 &kp 0x70011 &kp 0x70010 &kp 0x70036 &kp 0x70037 &th 0x70031 0x70038 &th 0x60700e0 0x8070035 &kp 0x700e8 &lt 0x2 0x7002c &lt 0x6 0x7002b &lt 0x4 0x70028 &lt 0x3 0x7002a &kp 0x7007f >;
			sensor-bindings = < &inc_dec_kp 0x807002e 0x807002d >, < &inc_dec_kp 0xc00e9 0xc00ea >;
		};
		nav {
			bindings = < &trans &kp 0x7001e &kp 0x7001f &kp 0x70020 &kp 0x70021 &kp 0x70022 &trans &th 0x7004d 0x7004e &kp 0x70052 &th 0x7004a 0x7004b &trans &trans &trans &hml 0x700e1 0x7001e &hml 0x700e0 0x7001f &hml 0x700e2 0x70020 &hml 0x700e3 0x70021 &hml 0x60700e0 0x70022 &kp 0xa07001d &kp 0x70050 &kp 0x70051 &kp 0x7004f &kp 0x807001d &trans &trans &kp 0x70023 &kp 0x70024 &kp 0x70025 &kp 0x70026 &kp 0x70027 &trans &th 0x807001b 0x8070006 &th 0x8070019 0xa070019 &kp 0x807001b &trans &trans &trans &trans &trans &trans &trans &trans >;
			sensor-bindings = < &inc_dec_kp 0x7004b 0x7004e >, < &inc_dec_kp 0x7004b 0x7004e >;
		};
		num {
			bindings = < &trans &kp 0x70038 &kp 0x2070025 &kp 0x7002d &kp 0x207002e &kp 0x2070022 &kp 0x2070023 &th 0x70085 0x70063 &kp 0x2070022 &kp 0x2070026 &kp 0x2070027 &trans &trans &kp 0x7001e &kp 0x7001f &kp 0x70020 &kp 0x70021 &kp 0x70022 &kp 0x70023 &kp 0x70024 &kp 0x70025 &kp 0x70026 &kp 0x70027 &trans &trans &kp 0x70023 &kp 0x70024 &kp 0x70025 &kp 0x70026 &kp 0x70027 &kp 0x70067 &kp 0x70057 &kp 0x70056 &kp 0x70055 &kp 0x70054 &trans &trans &trans &trans &trans &trans &trans >;
			sensor-bindings = < &inc_dec_kp 0x7004f 0x70050 >, < &enc_num >;
		};
		symbol {
			bindings = < &trans &kp 0x207001e &kp 0x207001f &kp 0x2070020 &kp 0x2070021 &kp 0x2070022 &kp 0x2070023 &kp 0x2070024 &kp 0x2070025 &kp 0x4070020 &kp 0x70035 &trans &trans &th 0x2070037 0x2070036 &th 0x70030 0x7002f &th 0x2070030 0x207002f &th 0x2070027 0x2070026 &kp 0x7002e &trans &kp 0x7002d &th 0x207002d 0x2070032 &kp 0x7002e &kp 0x2070031 &trans &trans &trans &trans &trans &trans &trans &trans &trans &trans &trans &trans &trans &kp 0x700e2 &trans &trans &trans &trans &th 0x3070013 0x70028 >;
			sensor-bindings = < &inc_dec_kp 0x7004f 0x70050 >, < &inc_dec_kp 0x70052 0x70051 >;
		};
		mouse {
			bindings = < &trans &trans &trans &trans &trans &trans &trans &trans &trans &trans &trans &trans &trans &trans &trans &trans &trans &trans &trans &trans &trans &trans &trans &trans &trans &trans &trans &trans &trans &trans &trans &trans &trans &trans &trans &trans &trans &trans &trans &trans &trans &trans >;
			sensor-bindings = < &inc_dec_kp 0x0 0x0 >, < &inc_dec_kp 0x0 0x0 >;
		};
		util {
			bindings = < &trans &trans &trans &trans &trans &trans &trans &trans &trans &trans &trans &trans &trans &trans &trans &trans &trans &trans &trans &trans &trans &trans &trans &trans &trans &trans &trans &trans &trans &trans &trans &trans &trans &trans &trans &trans &trans &trans &trans &trans &trans &trans >;
			sensor-bindings = < &inc_dec_kp 0x0 0x0 >, < &inc_dec_kp 0x0 0x0 >;
		};
		figma {
			bindings = < &trans &trans &trans &trans &trans &trans &trans &trans &trans &trans &trans &trans &trans &trans &trans &trans &trans &trans &trans &trans &trans &trans &trans &trans &trans &trans &trans &trans &trans &trans &trans &trans &trans &trans &trans &trans &trans &trans &trans &trans &trans &trans >;
			sensor-bindings = < &inc_dec_kp 0x0 0x0 >, < &inc_dec_kp 0x0 0x0 >;
		};
	};
	conditional_layers {
		compatible = "zmk,conditional-layers";
		thumbs_main {
			if-layers = < 0x2 0x3 >;
			then-layer = < 0x1 >;
		};
	};
};
